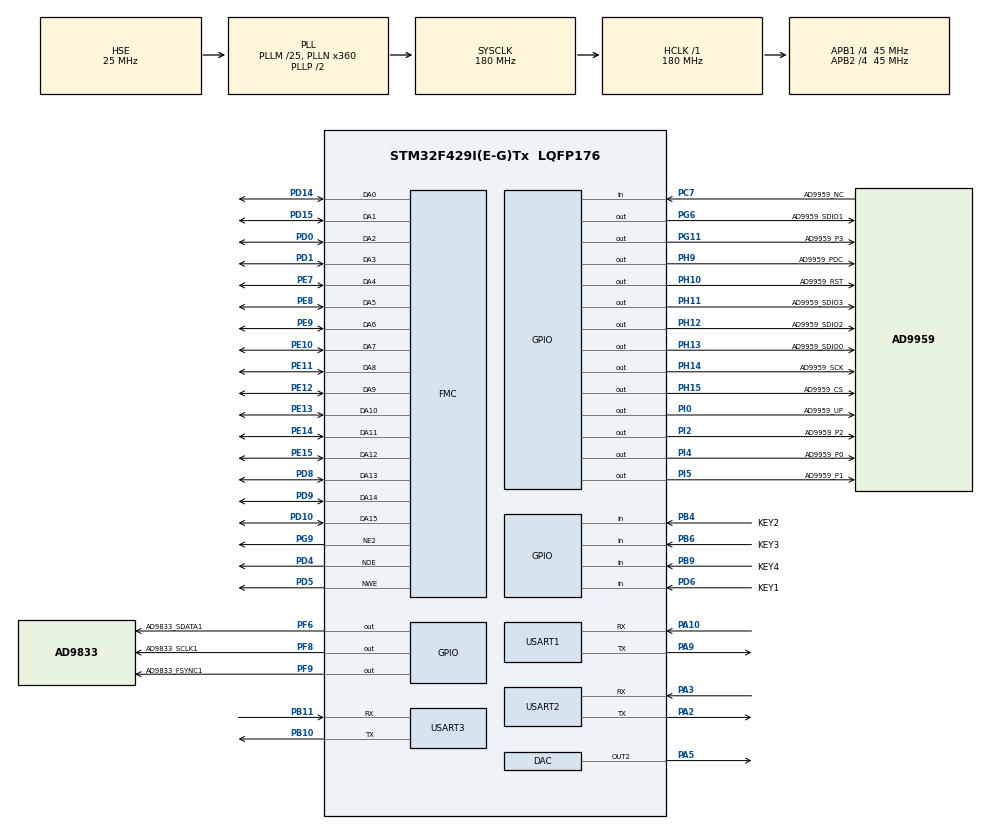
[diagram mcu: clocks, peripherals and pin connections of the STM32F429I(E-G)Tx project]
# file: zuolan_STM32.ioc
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DAC.DAC_OutputBuffer=DAC_OUTPUTBUFFER_ENABLE
DAC.DAC_OutputBuffer2=DAC_OUTPUTBUFFER_ENABLE
FMC.AddressHoldTime2=1
FMC.AddressSetupTime2=3
FMC.BusTurnAroundDuration2=0
FMC.DataSetupTime2=6
FMC.WriteOperation2=FMC_WRITE_OPERATION_ENABLE
Mcu.Family=STM32F4
Mcu.Name=STM32F429I(E-G)Tx
Mcu.Package=LQFP176
NVIC.PriorityGroup=NVIC_PRIORITYGROUP_4
NVIC.USART1_IRQn=true\:0\:0\:false\:false\:true\:true\:true\:true
NVIC.USART2_IRQn=true\:0\:0\:false\:false\:true\:true\:true\:true
NVIC.USART3_IRQn=true\:0\:0\:false\:false\:true\:true\:true\:true
PA10.Mode=Asynchronous
PA10.Signal=USART1_RX
PA13.Mode=Serial_Wire
PA13.Signal=SYS_JTMS-SWDIO
PA14.Mode=Serial_Wire
PA14.Signal=SYS_JTCK-SWCLK
PA2.Mode=Asynchronous
PA2.Signal=USART2_TX
PA3.Mode=Asynchronous
PA3.Signal=USART2_RX
PA5.Signal=COMP_DAC2_group
PA9.Mode=Asynchronous
PA9.Signal=USART1_TX
PB10.Mode=Asynchronous
PB10.Signal=USART3_TX
PB11.Mode=Asynchronous
PB11.Signal=USART3_RX
PB4.GPIO_Label=KEY2
PB4.GPIO_PuPd=GPIO_PULLUP
PB4.Signal=GPIO_Input
PB6.GPIO_Label=KEY3
PB6.GPIO_PuPd=GPIO_PULLUP
PB6.Signal=GPIO_Input
PB7.Signal=FMC_NL
PB9.GPIO_Label=KEY4
PB9.GPIO_PuPd=GPIO_PULLUP
PB9.Signal=GPIO_Input
PC7.GPIO_Label=AD9959_NC
PC7.GPIO_PuPd=GPIO_NOPULL
PC7.Signal=GPIO_Input
PD0.Signal=FMC_D2_DA2
PD1.Signal=FMC_D3_DA3
PD10.Signal=FMC_D15_DA15
PD14.Signal=FMC_D0_DA0
PD15.Signal=FMC_D1_DA1
PD4.Signal=FMC_NOE
PD5.Signal=FMC_NWE
PD6.GPIO_Label=KEY1
PD6.GPIO_PuPd=GPIO_PULLUP
PD6.Signal=GPIO_Input
PD8.Signal=FMC_D13_DA13
PD9.Signal=FMC_D14_DA14
PE10.Signal=FMC_D7_DA7
PE11.Signal=FMC_D8_DA8
PE12.Signal=FMC_D9_DA9
PE13.Signal=FMC_D10_DA10
PE14.Signal=FMC_D11_DA11
PE15.Signal=FMC_D12_DA12
PE7.Signal=FMC_D4_DA4
PE8.Signal=FMC_D5_DA5
PE9.Signal=FMC_D6_DA6
PF6.GPIO_Label=AD9833_SDATA1
PF6.Signal=GPIO_Output
PF8.GPIO_Label=AD9833_SCLK1
PF8.Signal=GPIO_Output
PF9.GPIO_Label=AD9833_FSYNC1
PF9.Signal=GPIO_Output
PG11.GPIO_Label=AD9959_P3
PG11.GPIO_PuPd=GPIO_NOPULL
PG11.GPIO_Speed=GPIO_SPEED_FREQ_HIGH
PG11.Signal=GPIO_Output
PG6.GPIO_Label=AD9959_SDIO1
PG6.GPIO_PuPd=GPIO_NOPULL
PG6.GPIO_Speed=GPIO_SPEED_FREQ_HIGH
PG6.Signal=GPIO_Output
PG9.Mode=NorPsramChipSelect2_2
PG9.Signal=FMC_NE2
PH0/OSC_IN.Mode=HSE-External-Oscillator
PH0/OSC_IN.Signal=RCC_OSC_IN
PH1/OSC_OUT.Mode=HSE-External-Oscillator
PH1/OSC_OUT.Signal=RCC_OSC_OUT
PH10.GPIO_Label=AD9959_RST
PH10.GPIO_PuPd=GPIO_NOPULL
PH10.GPIO_Speed=GPIO_SPEED_FREQ_HIGH
PH10.Signal=GPIO_Output
PH11.GPIO_Label=AD9959_SDIO3
PH11.GPIO_PuPd=GPIO_NOPULL
PH11.GPIO_Speed=GPIO_SPEED_FREQ_HIGH
PH11.Signal=GPIO_Output
PH12.GPIO_Label=AD9959_SDIO2
PH12.GPIO_PuPd=GPIO_NOPULL
PH12.GPIO_Speed=GPIO_SPEED_FREQ_HIGH
PH12.Signal=GPIO_Output
PH13.GPIO_Label=AD9959_SDIO0
PH13.GPIO_ModeDefaultOutputPP=GPIO_MODE_OUTPUT_PP
PH13.GPIO_PuPd=GPIO_NOPULL
PH13.GPIO_Speed=GPIO_SPEED_FREQ_HIGH
PH13.PinState=GPIO_PIN_RESET
PH13.Signal=GPIO_Output
PH14.GPIO_Label=AD9959_SCK
PH14.GPIO_PuPd=GPIO_NOPULL
PH14.GPIO_Speed=GPIO_SPEED_FREQ_HIGH
PH14.Signal=GPIO_Output
PH15.GPIO_Label=AD9959_CS
PH15.GPIO_PuPd=GPIO_NOPULL
PH15.GPIO_Speed=GPIO_SPEED_FREQ_HIGH
PH15.Signal=GPIO_Output
PH9.GPIO_Label=AD9959_PDC
PH9.GPIO_PuPd=GPIO_NOPULL
PH9.GPIO_Speed=GPIO_SPEED_FREQ_HIGH
PH9.Signal=GPIO_Output
PI0.GPIO_Label=AD9959_UP
PI0.GPIO_PuPd=GPIO_NOPULL
PI0.GPIO_Speed=GPIO_SPEED_FREQ_HIGH
PI0.Signal=GPIO_Output
PI2.GPIO_Label=AD9959_P2
PI2.GPIO_PuPd=GPIO_NOPULL
PI2.GPIO_Speed=GPIO_SPEED_FREQ_HIGH
PI2.Signal=GPIO_Output
PI4.GPIO_Label=AD9959_P0
PI4.GPIO_PuPd=GPIO_NOPULL
PI4.GPIO_Speed=GPIO_SPEED_FREQ_HIGH
PI4.Signal=GPIO_Output
PI5.GPIO_Label=AD9959_P1
PI5.GPIO_PuPd=GPIO_NOPULL
PI5.GPIO_Speed=GPIO_SPEED_FREQ_HIGH
PI5.Signal=GPIO_Output
ProjectManager.HeapSize=0x200
ProjectManager.StackSize=0x400
ProjectManager.TargetToolchain=MDK-ARM V5
RCC.48MHZClocksFreq_Value=90000000
RCC.AHBFreq_Value=180000000
RCC.APB1CLKDivider=RCC_HCLK_DIV4
RCC.APB1Freq_Value=45000000
RCC.APB1TimFreq_Value=90000000
RCC.APB2CLKDivider=RCC_HCLK_DIV4
RCC.APB2Freq_Value=45000000
RCC.APB2TimFreq_Value=90000000
RCC.CortexFreq_Value=180000000
RCC.EnbaleCSS=true
RCC.HCLKFreq_Value=180000000
RCC.HSE_VALUE=25000000
RCC.HSI_VALUE=16000000
RCC.LSE_VALUE=32768
RCC.PLLM=25
RCC.PLLN=360
RCC.PLLSourceVirtual=RCC_PLLSOURCE_HSE
RCC.SYSCLKFreq_VALUE=180000000
RCC.SYSCLKSource=RCC_SYSCLKSOURCE_PLLCLK
RCC.VCOOutputFreq_Value=360000000
SH.COMP_DAC2_group.0=DAC_OUT2,DAC_OUT2
SH.FMC_D0_DA0.0=FMC_DA0,16b-da2
SH.FMC_D10_DA10.0=FMC_DA10,16b-da2
SH.FMC_D11_DA11.0=FMC_DA11,16b-da2
SH.FMC_D12_DA12.0=FMC_DA12,16b-da2
SH.FMC_D13_DA13.0=FMC_DA13,16b-da2
SH.FMC_D14_DA14.0=FMC_DA14,16b-da2
SH.FMC_D15_DA15.0=FMC_DA15,16b-da2
SH.FMC_D1_DA1.0=FMC_DA1,16b-da2
SH.FMC_D2_DA2.0=FMC_DA2,16b-da2
SH.FMC_D3_DA3.0=FMC_DA3,16b-da2
SH.FMC_D4_DA4.0=FMC_DA4,16b-da2
SH.FMC_D5_DA5.0=FMC_DA5,16b-da2
SH.FMC_D6_DA6.0=FMC_DA6,16b-da2
SH.FMC_D7_DA7.0=FMC_DA7,16b-da2
SH.FMC_D8_DA8.0=FMC_DA8,16b-da2
SH.FMC_D9_DA9.0=FMC_DA9,16b-da2
SH.FMC_NL.0=FMC_NL
SH.FMC_NOE.0=FMC_NOE,MuxedPsram2
SH.FMC_NWE.0=FMC_NWE,MuxedPsram2
STMicroelectronics.X-CUBE-ALGOBUILD.1.4.0.LibraryCcDSPOoLibraryJjDSPOoLibrary=true
USART1.VirtualMode=VM_ASYNC
USART2.VirtualMode=VM_ASYNC
USART3.VirtualMode=VM_ASYNC
VP_STMicroelectronics.X-CUBE-ALGOBUILD_VS_DSPOoLibraryJjLibrary_1.4.0_1.4.0.Mode=DSPOoLibraryJjLibrary
board=custom

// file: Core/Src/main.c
/* USER CODE BEGIN Header */
/**
 ******************************************************************************
 * @file           : main.c
 * @brief          : Main program body
 ******************************************************************************
 * @attention
 *
 * Copyright (c) 2024 STMicroelectronics.
 * All rights reserved.
 *
 * This software is licensed under terms that can be found in the LICENSE file
 * in the root directory of this software component.
 * If no LICENSE file comes with this software, it is provided AS-IS.
 *
 ******************************************************************************
 */
/* USER CODE END Header */
#include "main.h"
#include "dac.h"
#include "usart.h"
#include "gpio.h"
#include "fmc.h"

/* USER CODE BEGIN Includes */

#include "bsp_system.h"
#include "g_signal_app.h"
/* USER CODE END Includes */

void SystemClock_Config(void);

int main(void)
{

  /* MCU Configuration--------------------------------------------------------*/

  /* Reset of all peripherals, Initializes the Flash interface and the Systick. */
  HAL_Init();

  /* Configure the system clock */
  SystemClock_Config();

  /* Initialize all configured peripherals */
  MX_GPIO_Init();
  MX_FMC_Init();
  MX_USART1_UART_Init();
  MX_USART2_UART_Init();
  MX_USART3_UART_Init();
  MX_DAC_Init();
  /* USER CODE BEGIN 2 */
  HAL_UART_Receive_IT(&huart1, &rxTemp1, 1);
  HAL_UART_Receive_IT(&huart2, &rxTemp2, 1);
  HAL_UART_Receive_IT(&huart3, &rxTemp3, 1);
  CTRL_INIT();
  GSignalApp_Init();
  scheduler_init();
  /* USER CODE END 2 */

  /* Infinite loop */
  while (1)
  {

    /* USER CODE BEGIN 3 */
    scheduler_run();
  }
  /* USER CODE END 3 */
}

void SystemClock_Config(void)
{
  RCC_OscInitTypeDef RCC_OscInitStruct = {0};
  RCC_ClkInitTypeDef RCC_ClkInitStruct = {0};

  /** Configure the main internal regulator output voltage
  */
  __HAL_RCC_PWR_CLK_ENABLE();
  __HAL_PWR_VOLTAGESCALING_CONFIG(PWR_REGULATOR_VOLTAGE_SCALE1);

  /** Initializes the RCC Oscillators according to the specified parameters
  * in the RCC_OscInitTypeDef structure.
  */
  RCC_OscInitStruct.OscillatorType = RCC_OSCILLATORTYPE_HSE;
  RCC_OscInitStruct.HSEState = RCC_HSE_ON;
  RCC_OscInitStruct.PLL.PLLState = RCC_PLL_ON;
  RCC_OscInitStruct.PLL.PLLSource = RCC_PLLSOURCE_HSE;
  RCC_OscInitStruct.PLL.PLLM = 25;
  RCC_OscInitStruct.PLL.PLLN = 360;
  RCC_OscInitStruct.PLL.PLLP = RCC_PLLP_DIV2;
  RCC_OscInitStruct.PLL.PLLQ = 4;
  if (HAL_RCC_OscConfig(&RCC_OscInitStruct) != HAL_OK)
  {
    Error_Handler();
  }

  /** Activate the Over-Drive mode
  */
  if (HAL_PWREx_EnableOverDrive() != HAL_OK)
  {
    Error_Handler();
  }

  /** Initializes the CPU, AHB and APB buses clocks
  */
  RCC_ClkInitStruct.ClockType = RCC_CLOCKTYPE_HCLK|RCC_CLOCKTYPE_SYSCLK
                              |RCC_CLOCKTYPE_PCLK1|RCC_CLOCKTYPE_PCLK2;
  RCC_ClkInitStruct.SYSCLKSource = RCC_SYSCLKSOURCE_PLLCLK;
  RCC_ClkInitStruct.AHBCLKDivider = RCC_SYSCLK_DIV1;
  RCC_ClkInitStruct.APB1CLKDivider = RCC_HCLK_DIV4;
  RCC_ClkInitStruct.APB2CLKDivider = RCC_HCLK_DIV4;

  if (HAL_RCC_ClockConfig(&RCC_ClkInitStruct, FLASH_LATENCY_5) != HAL_OK)
  {
    Error_Handler();
  }

  /** Enables the Clock Security System
  */
  HAL_RCC_EnableCSS();
}

void Error_Handler(void)
{
  __disable_irq();
  while (1)
  {
  }
}
